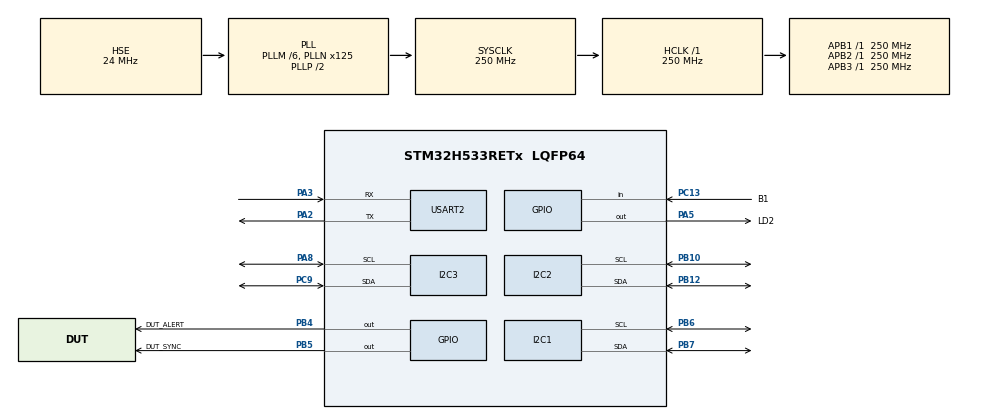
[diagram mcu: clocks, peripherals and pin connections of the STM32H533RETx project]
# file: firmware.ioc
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BOOTPATH.BootPathName=LEGACY
BOOTPATH.UserSelectedBootPath=LEGACY
CORTEX_M33_NS.Number-Cortex_Memory_Protection_Unit_Region0_OTP_RO_AREAS_Settings=MPU_REGION_NUMBER0
CORTEX_M33_NS.default_mode_Activation=1
CORTEX_M33_NS.userName=CORTEX_M33
I2C1.I2C_Rise_Time=300
I2C1.OwnAddress=0x08
I2C1.Timing=0x40703444
I2C2.I2C_Fall_Time=30
I2C2.I2C_Rise_Time=300
I2C2.OwnAddress=0x6B
I2C2.Timing=0x30803E58
I2C3.I2C_Fall_Time=30
I2C3.I2C_Rise_Time=300
I2C3.OwnAddress=0x55
I2C3.Timing=0x30803E58
Mcu.Family=STM32H5
Mcu.Name=STM32H533RETx
Mcu.Package=LQFP64
NVIC.I2C1_ER_IRQn=true\:0\:0\:false\:false\:true\:true\:true\:true
NVIC.I2C1_EV_IRQn=true\:0\:0\:false\:false\:true\:true\:true\:true
NVIC.I2C2_ER_IRQn=true\:0\:0\:false\:false\:true\:true\:true\:true
NVIC.I2C2_EV_IRQn=true\:0\:0\:false\:false\:true\:true\:true\:true
NVIC.I2C3_ER_IRQn=true\:0\:0\:false\:false\:true\:true\:true\:true
NVIC.I2C3_EV_IRQn=true\:0\:0\:false\:false\:true\:true\:true\:true
NVIC.PriorityGroup=NVIC_PRIORITYGROUP_4
NVIC.USART2_IRQn=true\:0\:0\:false\:false\:true\:true\:true\:true
PA13(JTMS/SWDIO).GPIO_Label=SWDIO
PA13(JTMS/SWDIO).Mode=Serial_Wire
PA13(JTMS/SWDIO).Signal=DEBUG_JTMS-SWDIO
PA14(JTCK/SWCLK).GPIO_Label=SWCLK
PA14(JTCK/SWCLK).Mode=Serial_Wire
PA14(JTCK/SWCLK).Signal=DEBUG_JTCK-SWCLK
PA15(JTDI).GPIO_Label=JTDI
PA15(JTDI).Signal=DEBUG_JTDI
PA2.Mode=Asynchronous
PA2.Signal=USART2_TX
PA3.Mode=Asynchronous
PA3.Signal=USART2_RX
PA5.GPIO_Label=LD2
PA5.Signal=GPIO_Output
PA8.GPIO_Speed=GPIO_SPEED_FREQ_VERY_HIGH
PA8.Mode=I2C
PA8.Signal=I2C3_SCL
PB10.GPIO_Speed=GPIO_SPEED_FREQ_VERY_HIGH
PB10.Mode=I2C
PB10.Signal=I2C2_SCL
PB12.GPIO_Speed=GPIO_SPEED_FREQ_VERY_HIGH
PB12.Mode=I2C
PB12.Signal=I2C2_SDA
PB3(JTDO/TRACESWO).GPIO_Label=SWO
PB3(JTDO/TRACESWO).Signal=DEBUG_JTDO-SWO
PB4(NJTRST).GPIO_Label=DUT_ALERT
PB4(NJTRST).GPIO_ModeDefaultOutputPP=GPIO_MODE_OUTPUT_OD
PB4(NJTRST).GPIO_PuPd=GPIO_NOPULL
PB4(NJTRST).PinState=GPIO_PIN_SET
PB4(NJTRST).Signal=GPIO_Output
PB5.GPIO_Label=DUT_SYNC
PB5.Signal=GPIO_Output
PB6.GPIO_Speed=GPIO_SPEED_FREQ_VERY_HIGH
PB6.Mode=I2C
PB6.Signal=I2C1_SCL
PB7.GPIO_Speed=GPIO_SPEED_FREQ_VERY_HIGH
PB7.Mode=I2C
PB7.Signal=I2C1_SDA
PC13.GPIO_Label=B1
PC13.Signal=GPIO_Input
PC9.GPIO_Speed=GPIO_SPEED_FREQ_VERY_HIGH
PC9.Mode=I2C
PC9.Signal=I2C3_SDA
PH0-OSC_IN(PH0).Mode=HSE-External-Oscillator
PH0-OSC_IN(PH0).Signal=RCC_OSC_IN
PH1-OSC_OUT(PH1).Mode=HSE-External-Oscillator
PH1-OSC_OUT(PH1).Signal=RCC_OSC_OUT
ProjectManager.HeapSize=0x200
ProjectManager.StackSize=0x400
ProjectManager.TargetToolchain=Makefile
RCC.ADCFreq_Value=250000000
RCC.AHBFreq_Value=250000000
RCC.APB1Freq_Value=250000000
RCC.APB1TimFreq_Value=250000000
RCC.APB2Freq_Value=250000000
RCC.APB2TimFreq_Value=250000000
RCC.APB3Freq_Value=250000000
RCC.CSI_VALUE=4000000
RCC.CortexFreq_Value=250000000
RCC.EPOD_VALUE=24000000
RCC.HCLKFreq_Value=250000000
RCC.HSE_VALUE=24000000
RCC.HSI48_VALUE=48000000
RCC.HSI_VALUE=64000000
RCC.I2C1CLockSelection=RCC_I2C1CLKSOURCE_PLL3R
RCC.I2C2CLockSelection=RCC_I2C2CLKSOURCE_PLL3R
RCC.I2C3CLockSelection=RCC_I2C3CLKSOURCE_PLL3R
RCC.LSE_VALUE=32768
RCC.LSIRC_VALUE=32000
RCC.PLL3M=3
RCC.PLL3N=16
RCC.PLL3Source=RCC_PLL3_SOURCE_HSE
RCC.PLLM=6
RCC.PLLN=125
RCC.PLLSourceVirtual=RCC_PLL1_SOURCE_HSE
RCC.SYSCLKFreq_VALUE=250000000
RCC.SYSCLKSource=RCC_SYSCLKSOURCE_PLLCLK
RCC.USBFreq_Value=48000000
RCC.VCOOutputFreq_Value=500000000
TIM2.PeriodNoDither=0xFFFFFFFF
TIM2.Prescaler=249
USART2.VirtualMode-Asynchronous=VM_ASYNC
VP_BOOTPATH_VS_BOOTPATH.Mode=BP_Activate
VP_CORTEX_M33_NS_VS_Hclk.Mode=Hclk_Mode
VP_ICACHE_VS_ICACHE.Mode=DirectMappedCache
VP_MEMORYMAP_VS_MEMORYMAP.Mode=CurAppReg
VP_PWR_VS_LPOM.Mode=PowerOptimisation
VP_PWR_VS_SECSignals.Mode=Security/Privilege
VP_TIM2_VS_ClockSourceINT.Mode=Internal
board=NUCLEO-H533RE

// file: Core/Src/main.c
/* USER CODE BEGIN Header */
/**
  ******************************************************************************
  * @file           : main.c
  * @brief          : Main program body
  ******************************************************************************
  * @attention
  *
  * Copyright (c) 2026 STMicroelectronics.
  * All rights reserved.
  *
  * This software is licensed under terms that can be found in the LICENSE file
  * in the root directory of this software component.
  * If no LICENSE file comes with this software, it is provided AS-IS.
  *
  ******************************************************************************
  */
/* USER CODE END Header */
#include "main.h"
#include "i2c.h"
#include "icache.h"
#include "tim.h"
#include "usart.h"
#include "gpio.h"

/* USER CODE BEGIN Includes */
/* [v0.1] loopback DUT hooks: App/ (see App/Inc/dut_app.h) */
#include "dut_app.h"
/* USER CODE END Includes */

void SystemClock_Config(void);
void PeriphCommonClock_Config(void);
static void MPU_Config(void);

int main(void)
{

  /* MCU Configuration--------------------------------------------------------*/

  /* MPU Configuration--------------------------------------------------------*/
  MPU_Config();

  /* Reset of all peripherals, Initializes the Flash interface and the Systick. */
  HAL_Init();

  /* Configure the system clock */
  SystemClock_Config();

  /* Configure the peripherals common clocks */
  PeriphCommonClock_Config();

  /* Initialize all configured peripherals */
  MX_GPIO_Init();
  MX_I2C1_Init();
  MX_I2C2_Init();
  MX_I2C3_Init();
  MX_ICACHE_Init();
  MX_TIM2_Init();
  MX_USART2_UART_Init();
  /* USER CODE BEGIN 2 */
  dut_app_init();
  /* USER CODE END 2 */

  /* Infinite loop */
  while (1)
  {

    /* USER CODE BEGIN 3 */
    dut_app_poll();
  }
  /* USER CODE END 3 */
}

void SystemClock_Config(void)
{
  RCC_OscInitTypeDef RCC_OscInitStruct = {0};
  RCC_ClkInitTypeDef RCC_ClkInitStruct = {0};

  /** Configure the main internal regulator output voltage
  */
  __HAL_PWR_VOLTAGESCALING_CONFIG(PWR_REGULATOR_VOLTAGE_SCALE0);

  while(!__HAL_PWR_GET_FLAG(PWR_FLAG_VOSRDY)) {}

  /** Initializes the RCC Oscillators according to the specified parameters
  * in the RCC_OscInitTypeDef structure.
  */
  RCC_OscInitStruct.OscillatorType = RCC_OSCILLATORTYPE_HSE;
  RCC_OscInitStruct.HSEState = RCC_HSE_ON;
  RCC_OscInitStruct.PLL.PLLState = RCC_PLL_ON;
  RCC_OscInitStruct.PLL.PLLSource = RCC_PLL1_SOURCE_HSE;
  RCC_OscInitStruct.PLL.PLLM = 6;
  RCC_OscInitStruct.PLL.PLLN = 125;
  RCC_OscInitStruct.PLL.PLLP = 2;
  RCC_OscInitStruct.PLL.PLLQ = 2;
  RCC_OscInitStruct.PLL.PLLR = 2;
  RCC_OscInitStruct.PLL.PLLRGE = RCC_PLL1_VCIRANGE_2;
  RCC_OscInitStruct.PLL.PLLVCOSEL = RCC_PLL1_VCORANGE_WIDE;
  RCC_OscInitStruct.PLL.PLLFRACN = 0;
  if (HAL_RCC_OscConfig(&RCC_OscInitStruct) != HAL_OK)
  {
    Error_Handler();
  }

  /** Initializes the CPU, AHB and APB buses clocks
  */
  RCC_ClkInitStruct.ClockType = RCC_CLOCKTYPE_HCLK|RCC_CLOCKTYPE_SYSCLK
                              |RCC_CLOCKTYPE_PCLK1|RCC_CLOCKTYPE_PCLK2
                              |RCC_CLOCKTYPE_PCLK3;
  RCC_ClkInitStruct.SYSCLKSource = RCC_SYSCLKSOURCE_PLLCLK;
  RCC_ClkInitStruct.AHBCLKDivider = RCC_SYSCLK_DIV1;
  RCC_ClkInitStruct.APB1CLKDivider = RCC_HCLK_DIV1;
  RCC_ClkInitStruct.APB2CLKDivider = RCC_HCLK_DIV1;
  RCC_ClkInitStruct.APB3CLKDivider = RCC_HCLK_DIV1;

  if (HAL_RCC_ClockConfig(&RCC_ClkInitStruct, FLASH_LATENCY_5) != HAL_OK)
  {
    Error_Handler();
  }

  /** Configure the programming delay
  */
  __HAL_FLASH_SET_PROGRAM_DELAY(FLASH_PROGRAMMING_DELAY_2);
}

void PeriphCommonClock_Config(void)
{
  RCC_PeriphCLKInitTypeDef PeriphClkInitStruct = {0};

  /** Initializes the peripherals clock
  */
  PeriphClkInitStruct.PeriphClockSelection = RCC_PERIPHCLK_I2C1|RCC_PERIPHCLK_I2C2
                              |RCC_PERIPHCLK_I2C3;
  PeriphClkInitStruct.PLL3.PLL3Source = RCC_PLL3_SOURCE_HSE;
  PeriphClkInitStruct.PLL3.PLL3M = 3;
  PeriphClkInitStruct.PLL3.PLL3N = 16;
  PeriphClkInitStruct.PLL3.PLL3P = 2;
  PeriphClkInitStruct.PLL3.PLL3Q = 2;
  PeriphClkInitStruct.PLL3.PLL3R = 2;
  PeriphClkInitStruct.PLL3.PLL3RGE = RCC_PLL3_VCIRANGE_1;
  PeriphClkInitStruct.PLL3.PLL3VCOSEL = RCC_PLL3_VCORANGE_WIDE;
  PeriphClkInitStruct.PLL3.PLL3FRACN = 0;
  PeriphClkInitStruct.PLL3.PLL3ClockOut = RCC_PLL3_DIVR;
  PeriphClkInitStruct.I2c1ClockSelection = RCC_I2C1CLKSOURCE_PLL3R;
  PeriphClkInitStruct.I2c2ClockSelection = RCC_I2C2CLKSOURCE_PLL3R;
  PeriphClkInitStruct.I2c3ClockSelection = RCC_I2C3CLKSOURCE_PLL3R;
  if (HAL_RCCEx_PeriphCLKConfig(&PeriphClkInitStruct) != HAL_OK)
  {
    Error_Handler();
  }
}

 /* MPU Configuration */

void MPU_Config(void)
{
  MPU_Region_InitTypeDef MPU_InitStruct = {0};
  MPU_Attributes_InitTypeDef MPU_AttributesInit = {0};

  /* Disables the MPU */
  HAL_MPU_Disable();

  /** Initializes and configures the Region 0 and the memory to be protected
  */
  MPU_InitStruct.Enable = MPU_REGION_ENABLE;
  MPU_InitStruct.Number = MPU_REGION_NUMBER0;
  MPU_InitStruct.BaseAddress = 0x08FFF000;
  MPU_InitStruct.LimitAddress = 0x08FFFFFF;
  MPU_InitStruct.AttributesIndex = MPU_ATTRIBUTES_NUMBER0;
  MPU_InitStruct.AccessPermission = MPU_REGION_ALL_RO;
  MPU_InitStruct.DisableExec = MPU_INSTRUCTION_ACCESS_DISABLE;
  MPU_InitStruct.IsShareable = MPU_ACCESS_NOT_SHAREABLE;

  HAL_MPU_ConfigRegion(&MPU_InitStruct);

  /** Initializes and configures the Attribute 0 and the memory to be protected
  */
  MPU_AttributesInit.Number = MPU_ATTRIBUTES_NUMBER0;
  MPU_AttributesInit.Attributes = INNER_OUTER(MPU_NOT_CACHEABLE);

  HAL_MPU_ConfigMemoryAttributes(&MPU_AttributesInit);
  /* Enables the MPU */
  HAL_MPU_Enable(MPU_PRIVILEGED_DEFAULT);

}

void Error_Handler(void)
{
  __disable_irq();
  while (1)
  {
  }
}
